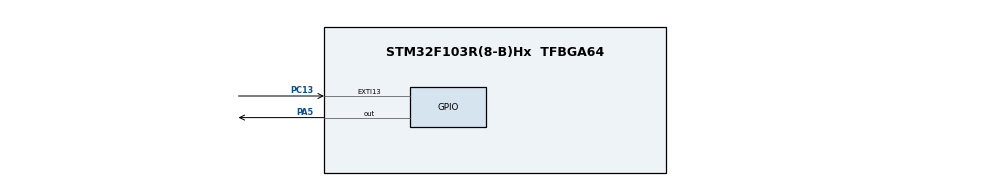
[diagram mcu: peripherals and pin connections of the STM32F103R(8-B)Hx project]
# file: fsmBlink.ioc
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Mcu.Family=STM32F1
Mcu.Name=STM32F103R(8-B)Hx
Mcu.Package=TFBGA64
NVIC.EXTI15_10_IRQn=true\:0\:0\:false\:false\:true\:true\:true\:true
NVIC.PriorityGroup=NVIC_PRIORITYGROUP_4
NVIC.TIM1_UP_IRQn=true\:0\:0\:false\:false\:true\:true\:true\:true
PA5.Signal=GPIO_Output
PC13-TAMPER-RTC.GPIO_ModeDefaultEXTI=GPIO_MODE_IT_RISING
PC13-TAMPER-RTC.Signal=GPXTI13
ProjectManager.HeapSize=0x200
ProjectManager.StackSize=0x400
ProjectManager.TargetToolchain=STM32CubeIDE
RCC.APB1Freq_Value=8000000
RCC.APB2Freq_Value=8000000
TIM1.AutoReloadPreload=TIM_AUTORELOAD_PRELOAD_DISABLE
TIM1.Period=499
TIM1.Prescaler=7999
VP_TIM1_VS_ClockSourceINT.Mode=Internal
board=custom

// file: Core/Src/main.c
/* USER CODE BEGIN Header */
/**
  ******************************************************************************
  * @file           : main.c
  * @brief          : Main program body
  ******************************************************************************
  * @attention
  *
  * Copyright (c) 2023 STMicroelectronics.
  * All rights reserved.
  *
  * This software is licensed under terms that can be found in the LICENSE file
  * in the root directory of this software component.
  * If no LICENSE file comes with this software, it is provided AS-IS.
  *
  ******************************************************************************
  */
/* USER CODE END Header */
#include "main.h"

/* USER CODE BEGIN Includes */

#include "app.h"
#include "bsp.h"

/* USER CODE END Includes */

TIM_HandleTypeDef htim1;

/* USER CODE BEGIN PV */

TimeApp myapp;
Timer *A_Timer = &myapp.timer;
Active *A_TimeApp = &myapp.super;

/* USER CODE END PV */

void SystemClock_Config(void);
static void MX_GPIO_Init(void);
static void MX_TIM1_Init(void);

int main(void)
{

  /* MCU Configuration--------------------------------------------------------*/

  /* Reset of all peripherals, Initializes the Flash interface and the Systick. */
  HAL_Init();

  /* Configure the system clock */
  SystemClock_Config();

  /* Initialize all configured peripherals */
  MX_GPIO_Init();
  MX_TIM1_Init();
  /* USER CODE BEGIN 2 */

  // Clear the timer interrupt, if any

  TIMER_Ctr(&myapp);
  TIM_Ctr(&myapp.timer, A_TimeApp, &htim1, TIMEOUT_SIG);

  // Handles all events, doesn't return.
  ACT_EventLoop(A_TimeApp);

  /* USER CODE END 2 */

  /* Infinite loop */
  while (1)
  {

  }
}

void SystemClock_Config(void)
{
  RCC_OscInitTypeDef RCC_OscInitStruct = {0};
  RCC_ClkInitTypeDef RCC_ClkInitStruct = {0};

  /** Initializes the RCC Oscillators according to the specified parameters
  * in the RCC_OscInitTypeDef structure.
  */
  RCC_OscInitStruct.OscillatorType = RCC_OSCILLATORTYPE_HSI;
  RCC_OscInitStruct.HSIState = RCC_HSI_ON;
  RCC_OscInitStruct.HSICalibrationValue = RCC_HSICALIBRATION_DEFAULT;
  RCC_OscInitStruct.PLL.PLLState = RCC_PLL_NONE;
  if (HAL_RCC_OscConfig(&RCC_OscInitStruct) != HAL_OK)
  {
    Error_Handler();
  }

  /** Initializes the CPU, AHB and APB buses clocks
  */
  RCC_ClkInitStruct.ClockType = RCC_CLOCKTYPE_HCLK|RCC_CLOCKTYPE_SYSCLK
                              |RCC_CLOCKTYPE_PCLK1|RCC_CLOCKTYPE_PCLK2;
  RCC_ClkInitStruct.SYSCLKSource = RCC_SYSCLKSOURCE_HSI;
  RCC_ClkInitStruct.AHBCLKDivider = RCC_SYSCLK_DIV1;
  RCC_ClkInitStruct.APB1CLKDivider = RCC_HCLK_DIV1;
  RCC_ClkInitStruct.APB2CLKDivider = RCC_HCLK_DIV1;

  if (HAL_RCC_ClockConfig(&RCC_ClkInitStruct, FLASH_LATENCY_0) != HAL_OK)
  {
    Error_Handler();
  }
}

static void MX_TIM1_Init(void)
{

  TIM_ClockConfigTypeDef sClockSourceConfig = {0};
  TIM_MasterConfigTypeDef sMasterConfig = {0};

  htim1.Instance = TIM1;
  htim1.Init.Prescaler = 7999;
  htim1.Init.CounterMode = TIM_COUNTERMODE_UP;
  htim1.Init.Period = 499;
  htim1.Init.ClockDivision = TIM_CLOCKDIVISION_DIV1;
  htim1.Init.RepetitionCounter = 0;
  htim1.Init.AutoReloadPreload = TIM_AUTORELOAD_PRELOAD_DISABLE;
  if (HAL_TIM_Base_Init(&htim1) != HAL_OK)
  {
    Error_Handler();
  }
  sClockSourceConfig.ClockSource = TIM_CLOCKSOURCE_INTERNAL;
  if (HAL_TIM_ConfigClockSource(&htim1, &sClockSourceConfig) != HAL_OK)
  {
    Error_Handler();
  }
  sMasterConfig.MasterOutputTrigger = TIM_TRGO_RESET;
  sMasterConfig.MasterSlaveMode = TIM_MASTERSLAVEMODE_DISABLE;
  if (HAL_TIMEx_MasterConfigSynchronization(&htim1, &sMasterConfig) != HAL_OK)
  {
    Error_Handler();
  }

}

static void MX_GPIO_Init(void)
{
  GPIO_InitTypeDef GPIO_InitStruct = {0};

  /* GPIO Ports Clock Enable */
  __HAL_RCC_GPIOC_CLK_ENABLE();
  __HAL_RCC_GPIOA_CLK_ENABLE();

  /*Configure GPIO pin Output Level */
  HAL_GPIO_WritePin(GPIOA, GPIO_PIN_5, GPIO_PIN_RESET);

  /*Configure GPIO pin : PC13 */
  GPIO_InitStruct.Pin = GPIO_PIN_13;
  GPIO_InitStruct.Mode = GPIO_MODE_IT_RISING;
  GPIO_InitStruct.Pull = GPIO_NOPULL;
  HAL_GPIO_Init(GPIOC, &GPIO_InitStruct);

  /*Configure GPIO pin : PA5 */
  GPIO_InitStruct.Pin = GPIO_PIN_5;
  GPIO_InitStruct.Mode = GPIO_MODE_OUTPUT_PP;
  GPIO_InitStruct.Pull = GPIO_NOPULL;
  GPIO_InitStruct.Speed = GPIO_SPEED_FREQ_LOW;
  HAL_GPIO_Init(GPIOA, &GPIO_InitStruct);

  /* EXTI interrupt init*/
  HAL_NVIC_SetPriority(EXTI15_10_IRQn, 0, 0);
  HAL_NVIC_EnableIRQ(EXTI15_10_IRQn);

}

void Error_Handler(void)
{
  __disable_irq();
  while (1)
  {
  }
}
